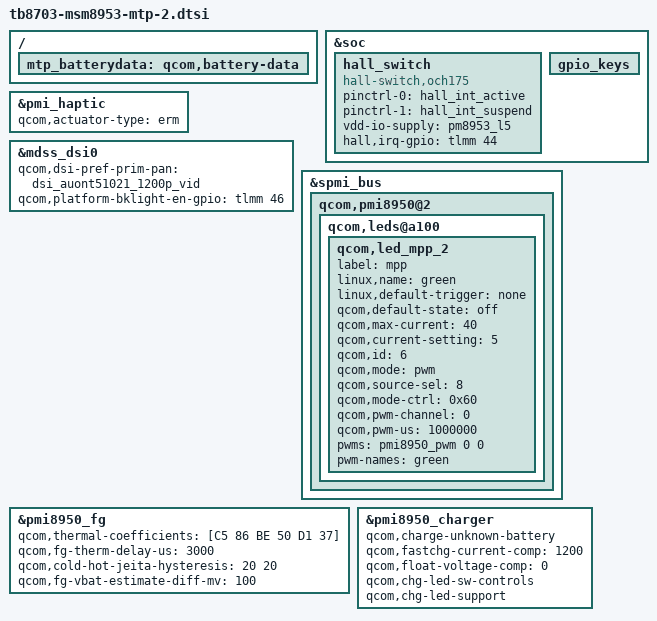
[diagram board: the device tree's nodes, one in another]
/*
 * Copyright (c) 2015-2016, The Linux Foundation. All rights reserved.
 *
 * This program is free software; you can redistribute it and/or modify
 * it under the terms of the GNU General Public License version 2 and
 * only version 2 as published by the Free Software Foundation.
 *
 * This program is distributed in the hope that it will be useful,
 * but WITHOUT ANY WARRANTY; without even the implied warranty of
 * MERCHANTABILITY or FITNESS FOR A PARTICULAR PURPOSE.  See the
 * GNU General Public License for more details.
 */

/*&spi_3 { // BLSP1 QUP3 
	spi-max-frequency = <16000000>;
	maxim_sti@0 {
		status = "disabled";
		compatible = "maxim,maxim_sti";
		reg = <0>;
		interrupt-parent = <&tlmm>;
		interrupts = <65 0>;
		spi-max-frequency = <16000000>;
		avdd-supply = <&pm8953_l10>;
		dvdd-supply = <&pm8953_l5>;
		maxim_sti,irq-gpio = <&tlmm 65 0x00>;
		maxim_sti,reset-gpio = <&tlmm 64 0x00>;
		maxim_sti,touch_fusion = "/vendor/bin/touch_fusion";
		maxim_sti,config_file = "/etc/firmware/qtc800s.cfg";
		maxim_sti,fw_name = "qtc800s.bin";
		pinctrl-names = "pmx_ts_active","pmx_ts_suspend",
						"pmx_ts_release";
		pinctrl-0 = <&ts_int_active &ts_reset_active>;
		pinctrl-1 = <&ts_int_suspend &ts_reset_suspend>;
		pinctrl-2 = <&ts_release>;
	};
};*/

&soc {
	hall_switch {
	       compatible = "hall-switch,och175";
	       pinctrl-names = "hall_active","hall_suspend";
	       pinctrl-0 = <&hall_int_active>;
	       pinctrl-1 = <&hall_int_suspend>;
	       //interrupt-parent = <&msm_gpio>;
	       //interrupts = <0 107 3>;
	       vdd-io-supply = <&pm8953_l5>;
	       interrupt-names = "hall_irq";
	       hall,irq-gpio = <&tlmm 44 0x2008>;
	};
	gpio_keys {
		/delete-node/ camera_focus;
		/delete-node/ camera_snapshot;
	};

	/delete-node/ hbtp;
};

&pmi_haptic{
	/*qcom,actuator-type = "lra";
	qcom,lra-auto-res-mode="qwd";
	qcom,lra-high-z="opt1";
	qcom,lra-res-cal-period = <0>;
	qcom,wave-play-rate-us = <4165>;*/
	status = "okay";
	qcom,actuator-type = "erm";
};


&mdss_dsi0 {
	/delete-property/ lab-supply;
	/delete-property/ ibb-supply;
	/delete-property/ vdd-supply;
	qcom,dsi-pref-prim-pan = <&dsi_auont51021_1200p_vid>;
	/delete-property/ qcom,platform-reset-gpio;
	qcom,platform-bklight-en-gpio = <&tlmm 46 0>;
};


/*&dsi_truly_1080_vid {
	qcom,panel-supply-entries = <&dsi_panel_pwr_supply>;
	qcom,mdss-dsi-pan-enable-dynamic-fps;
	qcom,mdss-dsi-pan-fps-update = "dfps_immediate_clk_mode";
};

&dsi_truly_1080_cmd {
	qcom,panel-supply-entries = <&dsi_panel_pwr_supply>;
	qcom,ulps-enabled;
	qcom,partial-update-enabled;
	qcom,panel-roi-alignment = <2 2 4 2 1080 2>;
};*/


/*&mem_client_3_size {
	qcom,peripheral-size = <0x500000>;
};*/



/*&pm8953_typec {
	ss-mux-supply = <&pm8953_l13>;
	qcom,ssmux-gpio = <&tlmm 139 GPIO_ACTIVE_HIGH>;
	pinctrl-names = "default";
	pinctrl-0 = <&typec_ssmux_config>;
};*/

&spmi_bus {
	qcom,pmi8950@2 {
		qcom,leds@a100 {
			status = "okay";
			qcom,led_mpp_2 {
				label = "mpp";
				linux,name = "green";
				linux,default-trigger = "none";
				qcom,default-state = "off";
				qcom,max-current = <40>;
				qcom,current-setting = <5>;
				qcom,id = <6>;
				qcom,mode = "pwm"; //pwm mode 
				qcom,source-sel = <8>;//DTEST1 
				qcom,mode-ctrl = <0x60>; //current sink 
				qcom,pwm-channel = <0>; 
				qcom,pwm-us = <1000000>;//original period is 1 second 
				pwms = <&pmi8950_pwm 0 0>; 
				pwm-names="green"; // add this 
			};
		};
	};
};

/{
	mtp_batterydata: qcom,battery-data {
		/delete-node/ qcom,ascent-3450mah;
		/delete-node/ qcom,itech-3000mah;
		#include "batterydata-SCUD-4250mAh.dtsi"
		#include "batterydata-SCUD2-4250mAh.dtsi"
		#include "batterydata-ATL-4250mAh.dtsi"
	};
};

&pmi8950_fg {
	qcom,thermal-coefficients = [C5 86 BE 50 D1 37];
	qcom,fg-therm-delay-us = <3000>;
	qcom,cold-hot-jeita-hysteresis = <20 20>;
	qcom,fg-vbat-estimate-diff-mv = <100>;
};

&pmi8950_charger {
	qcom,charge-unknown-battery;
	qcom,fastchg-current-comp = <1200>;
	qcom,float-voltage-comp = <0>;
	qcom,chg-led-sw-controls;
	qcom,chg-led-support;
	/delete-property/ qcom,force-aicl-rerun;
	/delete-property/ qcom,aicl-rerun-period-s;
	/delete-property/ qcom,external-typec;
	/delete-property/ qcom,typec-psy-name;
};
